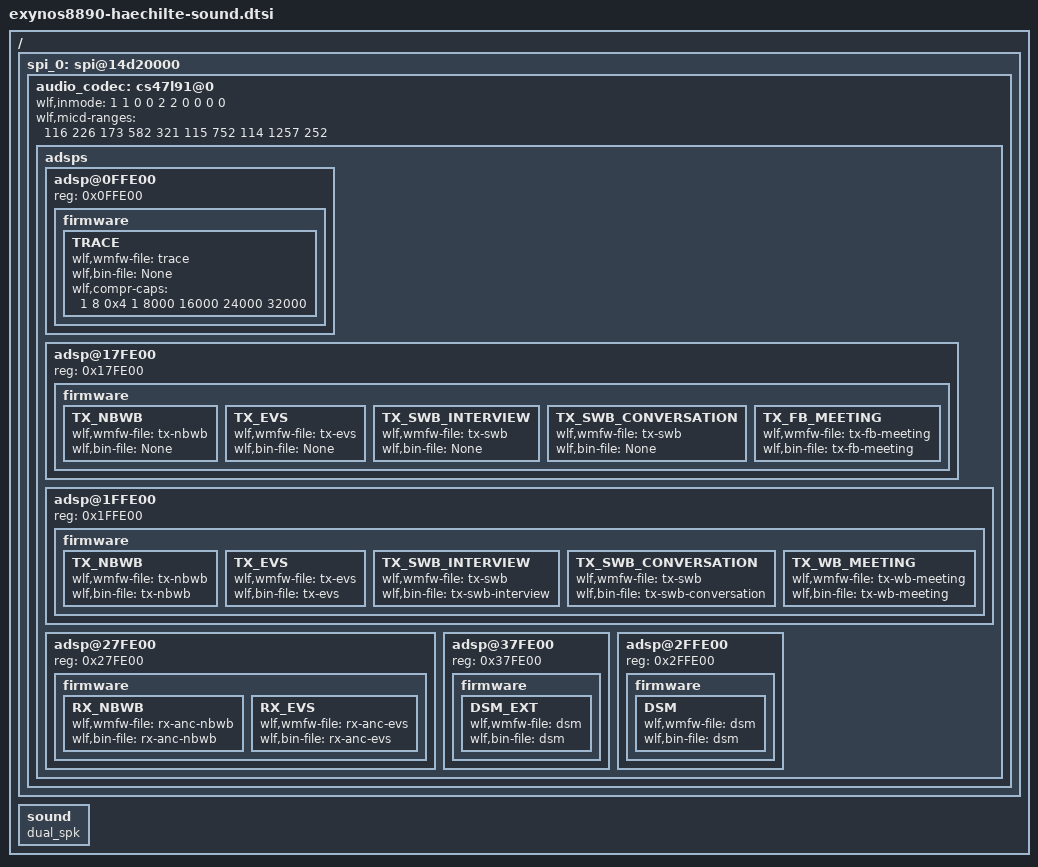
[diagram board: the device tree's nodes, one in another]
/*
 * SAMSUNG Haehi Sound Card Device Tree Source
 *
 * Copyright (c) 2016 Samsung Electronics Co., Ltd.
 *		http://www.samsung.com
 *
 * This program is free software; you can redistribute it and/or modify
 * it under the terms of the GNU General Public License version 2 as
 * published by the Free Software Foundation.
*/

/ {
	spi_0: spi@14d20000 {
		audio_codec: cs47l91@0 {
			wlf,inmode = <1 1 0 0 2 2 0 0 0 0>;
			/delete-property/ wlf,hs-mic;
			wlf,micd-ranges = <
				116 226
				173 582
				321 115
				752 114
				1257 252
			>;

			adsps {
				#address-cells = <1>;
				#size-cells = <0>;

				adsp@0FFE00 {
					reg = <0x0FFE00>;
					firmware {
						TRACE {
							wlf,wmfw-file = "trace";
							wlf,bin-file = "None";
							wlf,compr-caps = <1 8 0x4 1 8000 16000 24000 32000>;
						};
					};
				};
				adsp@17FE00 {
					reg = <0x17FE00>;
					firmware {
						TX_NBWB {
							wlf,wmfw-file = "tx-nbwb";
							wlf,bin-file = "None";
						};
						TX_EVS {
							wlf,wmfw-file = "tx-evs";
							wlf,bin-file = "None";
						};
						TX_SWB_INTERVIEW {
							wlf,wmfw-file = "tx-swb";
							wlf,bin-file = "None";
						};
						TX_SWB_CONVERSATION {
							wlf,wmfw-file = "tx-swb";
							wlf,bin-file = "None";
						};
						TX_FB_MEETING {
							wlf,wmfw-file = "tx-fb-meeting";
							wlf,bin-file = "tx-fb-meeting";
						};
					};
				};
				adsp@1FFE00 {
					reg = <0x1FFE00>;
					firmware {
						TX_NBWB {
							wlf,wmfw-file = "tx-nbwb";
							wlf,bin-file = "tx-nbwb";
						};
						TX_EVS {
							wlf,wmfw-file = "tx-evs";
							wlf,bin-file = "tx-evs";
						};
						TX_SWB_INTERVIEW {
							wlf,wmfw-file = "tx-swb";
							wlf,bin-file = "tx-swb-interview";
						};
						TX_SWB_CONVERSATION {
							wlf,wmfw-file = "tx-swb";
							wlf,bin-file = "tx-swb-conversation";
						};
						TX_WB_MEETING {
							wlf,wmfw-file = "tx-wb-meeting";
							wlf,bin-file = "tx-wb-meeting";
						};
					};
				};
				adsp@27FE00 {
					reg = <0x27FE00>;
					firmware {
						RX_NBWB {
							wlf,wmfw-file = "rx-anc-nbwb";
							wlf,bin-file = "rx-anc-nbwb";
						};
						RX_EVS {
							wlf,wmfw-file = "rx-anc-evs";
							wlf,bin-file = "rx-anc-evs";
						};
					};
				};
				adsp@37FE00 {
					reg = <0x37FE00>;
					/delete-node/ firmware;
					firmware {
						DSM_EXT {
							wlf,wmfw-file = "dsm";
							wlf,bin-file = "dsm";
						};
					};
				};
				adsp@2FFE00 {
					reg = <0x2FFE00>;
					firmware {
						DSM {
							wlf,wmfw-file = "dsm";
							wlf,bin-file = "dsm";
						};
					};
				};
			};
		};
	};

	sound {
		dual_spk;
	};
};
